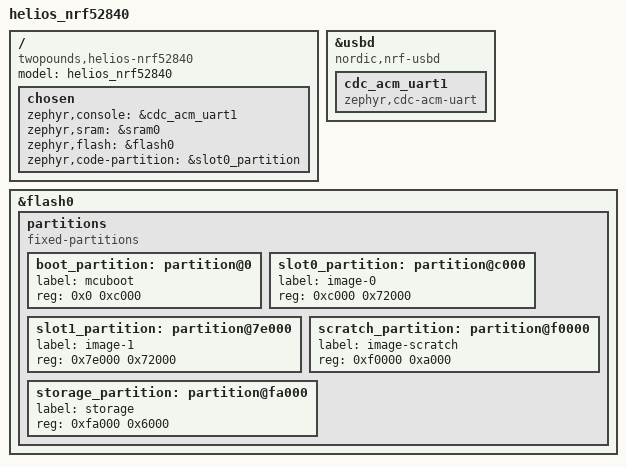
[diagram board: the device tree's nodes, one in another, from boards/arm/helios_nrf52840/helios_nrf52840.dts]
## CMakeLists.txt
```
# SPDX-License-Identifier: Apache-2.0

cmake_minimum_required(VERSION 3.20.0)
# Re-direct the directory where the 'boards' directory is found from
# $ZEPHYR_BASE to this directory.
list(PREPEND BOARD_ROOT ${CMAKE_CURRENT_SOURCE_DIR})

# you can redefine the log levels for the serial modules like this (1=Error,2=Warning,3=Info,4=Debug):
add_compile_definitions(SERIAL_LOG_LEVEL=4 BLE_SERIAL_LOG_LEVEL=3)

find_package(Zephyr REQUIRED HINTS $ENV{ZEPHYR_BASE})
project(Helios)

target_sources(app PRIVATE src/main.c src/serial.c src/serial_internal.c src/uart_serial.c src/ble_serial.c src/cmd_parser.c)
```

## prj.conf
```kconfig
#logging
CONFIG_LOG=y
CONFIG_LOG_DEFAULT_LEVEL=3
CONFIG_LOG_BACKEND_RTT=y
CONFIG_LOG_BACKEND_UART=n

#bluetooth
CONFIG_BT=y
CONFIG_BT_PERIPHERAL=y
CONFIG_BT_NUS=y
CONFIG_BT_DEVICE_NAME="Helios"
CONFIG_BT_MAX_CONN=1
CONFIG_BT_LL_SOFTDEVICE=y

#adc
CONFIG_ADC=y

#increase bt throughput
#CONFIG_BT_GATT_CLIENT=y
#CONFIG_BT_BUF_ACL_RX_SIZE=251
#CONFIG_BT_BUF_ACL_TX_SIZE=251
#CONFIG_BT_L2CAP_TX_MTU=257
#CONFIG_BT_CTLR_DATA_LENGTH_MAX=251
#CONFIG_BT_CTLR_ADV_DATA_LEN_MAX=256
```

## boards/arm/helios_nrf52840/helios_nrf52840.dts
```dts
// Copyright (c) 2023 Nordic Semiconductor ASA
// SPDX-License-Identifier: Apache-2.0

/dts-v1/;
#include <nordic/nrf52840_qiaa.dtsi>

/ {
	model = "helios_nrf52840";
	compatible = "twopounds,helios-nrf52840";

	chosen {
		zephyr,console = &cdc_acm_uart1; // original from manuel
		zephyr,sram = &sram0;
		zephyr,flash = &flash0;
		zephyr,code-partition = &slot0_partition;
	};
};

zephyr_udc0: &usbd {
	compatible = "nordic,nrf-usbd";
	status = "okay";
	cdc_acm_uart1: cdc_acm_uart1 {
		compatible = "zephyr,cdc-acm-uart";
	};
};


&flash0 {
	partitions {
		compatible = "fixed-partitions";
		#address-cells = <1>;
		#size-cells = <1>;

		boot_partition: partition@0 {
			label = "mcuboot";
			reg = <0x0 0xc000>;
		};
		slot0_partition: partition@c000 {
			label = "image-0";
			reg = <0xc000 0x72000>;
		};
		slot1_partition: partition@7e000 {
			label = "image-1";
			reg = <0x7e000 0x72000>;
		};
		scratch_partition: partition@f0000 {
			label = "image-scratch";
			reg = <0xf0000 0xa000>;
		};
		storage_partition: partition@fa000 {
			label = "storage";
			reg = <0xfa000 0x6000>;
		};
	};
};
```

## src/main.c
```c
/*
 * Copyright (c) 2012-2014 Wind River Systems, Inc.
 *
 * SPDX-License-Identifier: Apache-2.0
 */

#include <zephyr/kernel.h>
#include <zephyr/bluetooth/bluetooth.h>
#include "serial.h"

void main(void)
{
	serial_enable(SERIAL_TYPE_UART|SERIAL_TYPE_BLE);
	serial_set_end_character_list("\n", 1);
	serial_sendf(K_FOREVER, "Hello World!\n");
	
	while (true)
	{
		serial_line_t const * p_line = serial_get_line(K_FOREVER);
		serial_send(K_FOREVER, p_line->p_data, p_line->len);
	   	serial_sendf(K_FOREVER, "Hello World\n");
	}
}
```

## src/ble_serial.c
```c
#include "ble_serial.h"

#include <stdio.h>

#include <zephyr/logging/log.h>
#include <zephyr/bluetooth/bluetooth.h>
#include <zephyr/bluetooth/gatt.h>
#include <bluetooth/services/nus.h>

#include "serial_internal.h"


#ifdef CONFIG_BT
#ifdef CONFIG_BT_PERIPHERAL
#ifdef CONFIG_BT_NUS
#ifdef CONFIG_BT_DEVICE_NAME
#if CONFIG_BT==1
#if CONFIG_BT_PERIPHERAL==1
#if CONFIG_BT_NUS==1
#define BLE_SERIAL_REQUIREMENTS_FULLFILLED 1
#endif
#endif
#endif
#endif
#endif
#endif
#endif

#ifdef BLE_SERIAL_REQUIREMENTS_FULLFILLED
//////////////////////////////////////////////////////////////////////////////////////////////////////////////////////////
// DEFINITIONS AND STATIC VARIABLES
#ifndef BLE_SERIAL_LOG_LEVEL
#ifdef SERIAL_LOG_LEVEL
#define BLE_SERIAL_LOG_LEVEL SERIAL_LOG_LEVEL
#else
#define BLE_SERIAL_LOG_LEVEL LOG_LEVEL_WRN
#endif // SERIAL_LOG_LEVEL
#endif // !BLE_SERIAL_LOG_LEVEL

#define LOG_MODULE_NAME ble_serial
LOG_MODULE_REGISTER(LOG_MODULE_NAME, BLE_SERIAL_LOG_LEVEL);

#ifndef BLE_SERIAL_INPUT_BUFFER_SIZE
#ifdef SERIAL_INPUT_BUFFER_SIZE
#define BLE_SERIAL_INPUT_BUFFER_SIZE SERIAL_INPUT_BUFFER_SIZE
#else
#define BLE_SERIAL_INPUT_BUFFER_SIZE 256
#endif // SERIAL_INPUT_BUFFER_SIZE
#endif // !BLE_SERIAL_BUFFER_SIZE

#ifndef BLE_SERIAL_OUTPUT_BUFFER_SIZE
#ifdef SERIAL_OUTPUT_BUFFER_SIZE
#define BLE_SERIAL_OUTPUT_BUFFER_SIZE SERIAL_OUTPUT_BUFFER_SIZE
#else
#define BLE_SERIAL_OUTPUT_BUFFER_SIZE 256
#endif // SERIAL_OUTPUT_BUFFER_SIZE
#endif // !BLE_SERIAL_BUFFER_SIZE

#ifndef BLE_SERIAL_CALLBACK_LIMIT
#define BLE_SERIAL_CALLBACK_LIMIT 1
#endif // !BLE_SERIAL_CALLBACK_LIMIT

#define DEVICE_NAME CONFIG_BT_DEVICE_NAME
#define DEVICE_NAME_LEN (sizeof(CONFIG_BT_DEVICE_NAME) - 1)

static const struct bt_data advertising_data[] = {
	BT_DATA_BYTES(BT_DATA_FLAGS, (BT_LE_AD_GENERAL | BT_LE_AD_NO_BREDR)),
	BT_DATA(BT_DATA_NAME_COMPLETE, DEVICE_NAME, DEVICE_NAME_LEN),
};

static K_SEM_DEFINE(sem_wait_init, 0, 1);
static K_SEM_DEFINE(sem_data_ready, 0, 1);
static K_SEM_DEFINE(sem_wait_for_tx, 1, 1);

static bool enabled = false;
static char input_buffer[BLE_SERIAL_INPUT_BUFFER_SIZE + 1];
static char output_buffer[BLE_SERIAL_OUTPUT_BUFFER_SIZE + 1];
static char line_buffer[BLE_SERIAL_INPUT_BUFFER_SIZE + 1];

static serial_internal_line_t line = { 
	.mutable = { 
	.len = 0,
	.p_buffer = line_buffer,
	},
};

static int start_index = 0;
static int bytes_in_buffer = 0;
static int bt_data_len = 20;

static char const * end_character_list = NULL;
static int end_character_count = 0;

static serial_event_callback_t callback_list[BLE_SERIAL_CALLBACK_LIMIT] = { NULL };
static serial_event_t event;

//////////////////////////////////////////////////////////////////////////////////////////////////////////////////////////


//////////////////////////////////////////////////////////////////////////////////////////////////////////////////////////
// STATIC FUNCTION DECLARATIONS
static void fire_callbacks(serial_event_t const * p_evt);
//////////////////////////////////////////////////////////////////////////////////////////////////////////////////////////


//////////////////////////////////////////////////////////////////////////////////////////////////////////////////////////
// EVENT HANDLERS
static void bt_ready(int err)
{
	if (err)
	{
		LOG_ERR("bt_enable returned %d", err);
	}
	else
	{
		k_sem_give(&sem_wait_init);
	}
}

static void connected(struct bt_conn *conn, uint8_t err)
{
	if (err)
	{
		LOG_ERR("Connect failed (err: %d)", err);
	}
	else
	{
		LOG_INF("Connected");
	}
	LOG_DBG("MTU size is: %d", bt_gatt_get_mtu(conn));
}

static void disconnected(struct bt_conn *conn, uint8_t reason)
{
	LOG_INF("Disconnected (Reason: %d)", reason);
}

static bool le_param_req(struct bt_conn *conn, struct bt_le_conn_param *param)
{
	LOG_DBG("Connection parameters requested: \
	            \n\tInterval-Min: %d \
	            \n\tInterval-Max: %d \
	            \n\tLatency: %d \
	            \n\tTimeout: %d",
		param->interval_min,
		param->interval_max,
		param->latency,
		param->timeout);
    
	LOG_DBG("MTU size is: %d", bt_gatt_get_mtu(conn));

	return true;
}

static void gatt_exchange_cb(struct bt_conn *conn, uint8_t err, struct bt_gatt_exchange_params *params)
{
	LOG_DBG("MTU size after exchange is: %d", bt_gatt_get_mtu(conn));
	bt_data_len = bt_gatt_get_mtu(conn) - 3;
}

static void le_param_updated(struct bt_conn *conn, uint16_t interval, uint16_t latency, uint16_t timeout)
{
	LOG_DBG("Connection parameters updated: \
	        \n\tInterval: %d \
	        \n\tLatency: %d \
	        \n\tTimeout: %d",
		interval,
		latency,
		timeout);
	
#ifdef CONFIG_BT_GATT_CLIENT
#if CONFIG_BT_GATT_CLIENT==1
	LOG_DBG("MTU size is: %d", bt_gatt_get_mtu(conn));
	static struct bt_gatt_exchange_params params = {
		.func = gatt_exchange_cb,
	};

	bt_gatt_exchange_mtu(conn, &params);
#endif
#endif
}

static void nus_received(struct bt_conn *conn, const uint8_t *const data, uint16_t len)
{
	int bytes_to_copy = len;
	while (bytes_to_copy > 0)
	{
		int buffer_index = (start_index + bytes_in_buffer) % BLE_SERIAL_INPUT_BUFFER_SIZE;
		int free_space = (BLE_SERIAL_INPUT_BUFFER_SIZE - buffer_index);
		int part_to_copy = (len < free_space) ? len : free_space;
		memcpy(input_buffer + buffer_index, data, part_to_copy);
		bytes_to_copy -= part_to_copy;
		bytes_in_buffer += part_to_copy;
	}
	k_sem_give(&sem_data_ready);
	LOG_DBG("Received %d bytes, %d bytes in buffer", len, bytes_in_buffer);
	event.type = SERIAL_EVENT_TYPE_NEW_DATA_RECEIVED;
	event.data.new_data.count = len;
	event.data.new_data.p_buf = data;
	fire_callbacks(&event);
}

static void nus_sent(struct bt_conn *conn)
{
	k_sem_give(&sem_wait_for_tx);
}

static void nus_send_enabled(enum bt_nus_send_status status)
{
	
}
//////////////////////////////////////////////////////////////////////////////////////////////////////////////////////////


//////////////////////////////////////////////////////////////////////////////////////////////////////////////////////////
// STATIC FUNCTIONS
static void fire_callbacks(serial_event_t const * p_evt)
{
	for (int i = 0; i < BLE_SERIAL_CALLBACK_LIMIT; i++)
	{
		if (callback_list[i] != NULL)
		{
			callback_list[i](p_evt);
		}
	}
}
//////////////////////////////////////////////////////////////////////////////////////////////////////////////////////////

serial_ret_code_t ble_serial_add_callback(serial_event_callback_t callback)
{
	for (int i = 0; i < BLE_SERIAL_CALLBACK_LIMIT; i++)
	{
		if (callback_list[i] == NULL)
		{
			callback_list[i] = callback;
			return SERIAL_RET_CODE_SUCCESS;
		}
	}
	return SERIAL_RET_CODE_ERROR_NO_MEMORY;
}

serial_ret_code_t ble_serial_remove_callback(serial_event_callback_t callback)
{
	for (int i = 0; i < BLE_SERIAL_CALLBACK_LIMIT; i++)
	{
		if (callback_list[i] == callback)
		{
			callback_list[i] = NULL;
			return SERIAL_RET_CODE_SUCCESS;
		}
	}
	return SERIAL_RET_CODE_ERROR_NO_MEMORY;
}

serial_ret_code_t ble_serial_enable()
{
	k_sem_reset(&sem_wait_init);
	
	static struct bt_conn_cb connection_callbacks = {
		.connected = connected,
		.disconnected = disconnected,
		.le_param_req = le_param_req,
		.le_param_updated = le_param_updated,
	};
	bt_conn_cb_register(&connection_callbacks);
	
	int err;
	err = bt_enable(bt_ready);
	if (err == -EALREADY)
	{
		LOG_INF("bt already enabled, will instead attach nus service to existing ble interface");
		return ble_serial_attach();
	}
	else if (err)
	{
		LOG_ERR("bt_enable returned %d", err);
		return SERIAL_RET_CODE_ERROR_DEVICE_NOT_READY;
	}
	err = k_sem_take(&sem_wait_init, K_MSEC(10));
	if (err)
	{
		LOG_ERR("bt_enable timed out %d", err);
		return SERIAL_RET_CODE_ERROR_DEVICE_NOT_READY;
	}
	
	static struct bt_nus_cb nus_callbacks = {
		.received = nus_received,
		.sent = nus_sent,
		.send_enabled = nus_send_enabled,
	};
	err = bt_nus_init(&nus_callbacks);
	if (err)
	{
		LOG_ERR("could not init nus (err = %d)", err);
		return SERIAL_RET_CODE_ERROR_DEVICE_NOT_READY;
	}
	
	struct bt_le_adv_param * adv_params = BT_LE_ADV_CONN;
	adv_params->interval_min = BT_GAP_ADV_FAST_INT_MIN_1;
	adv_params->interval_max = BT_GAP_ADV_FAST_INT_MAX_1;
	err = bt_le_adv_start(adv_params, advertising_data, ARRAY_SIZE(advertising_data), NULL, 0);
	if (err)
	{
		LOG_ERR("could not start advertising (err = %d)", err);
		return SERIAL_RET_CODE_ERROR_DEVICE_NOT_READY;
	}
	
	k_sem_give(&sem_wait_for_tx);
	enabled = true;
	
	return SERIAL_RET_CODE_SUCCESS;
}

serial_ret_code_t ble_serial_attach()
{
	static struct bt_conn_cb connection_callbacks = {
		.connected = connected,
		.disconnected = disconnected,
		.le_param_req = le_param_req,
		.le_param_updated = le_param_updated,
	};
	bt_conn_cb_register(&connection_callbacks);
	
	int err;
	static struct bt_nus_cb nus_callbacks = {
		.received = nus_received,
		.sent = nus_sent,
		.send_enabled = nus_send_enabled,
	};
	err = bt_nus_init(&nus_callbacks);
	if (err)
	{
		LOG_ERR("could not init nus (err = %d)", err);
		return SERIAL_RET_CODE_ERROR_DEVICE_NOT_READY;
	}
	
	k_sem_give(&sem_wait_for_tx);
	enabled = true;
	
	return SERIAL_RET_CODE_SUCCESS;
}

serial_ret_code_t ble_serial_disable()
{
	
	return SERIAL_RET_CODE_ERROR_UNKNOWN;
}

serial_ret_code_t ble_serial_detach()
{
	
	return SERIAL_RET_CODE_ERROR_UNKNOWN;
}

serial_line_t const * ble_serial_get_line(k_timeout_t timeout)
{
	LOG_DBG("getting next line");
	line.mutable.len = 0;
	if (!enabled)
	{
		LOG_ERR("ble_serial not enabled");
		return &(line.fixed);
	}
	
	return serial_internal_get_line(&sem_data_ready, timeout, &line, input_buffer, BLE_SERIAL_INPUT_BUFFER_SIZE, &start_index, &bytes_in_buffer, end_character_list, end_character_count, fire_callbacks);
}

serial_ret_code_t ble_serial_send(k_timeout_t timeout, char const * p_data, int len)
{
	if (len == 0) return SERIAL_RET_CODE_SUCCESS;
	
	if (k_sem_take(&sem_wait_for_tx, timeout) != 0)
	{
		LOG_WRN("uart tx busy");
		return SERIAL_RET_CODE_ERROR_BUSY;
	}
	
	serial_ret_code_t ret_code = SERIAL_RET_CODE_SUCCESS;
	int bytes_sent = 0;
	while (bytes_sent < len)
	{
		int bytes_to_send = ((len - bytes_sent) < bt_data_len) ? (len - bytes_sent) : bt_data_len;
		int err = bt_nus_send(NULL, p_data + bytes_sent, bytes_to_send);
		if (err != 0)
		{
			k_sem_give(&sem_wait_for_tx);
			if (err != -ENOTCONN)
			{
				LOG_ERR("bt_nus_send returned error: %d", err);
				ret_code = SERIAL_RET_CODE_ERROR_DEVICE_NOT_READY;
			}
			break;
		}
		bytes_sent += bytes_to_send;
		LOG_INF("%d bytes sent (of %d)", bytes_sent, len);
	}
	
	return ret_code;
}

serial_ret_code_t ble_serial_vsendf(k_timeout_t timeout, const char * format, va_list args)
{
	if (k_sem_take(&sem_wait_for_tx, timeout) != 0)
	{
		LOG_WRN("uart tx busy");
		return SERIAL_RET_CODE_ERROR_BUSY;
	}
	k_sem_give(&sem_wait_for_tx);
	
	int len = vsnprintf(output_buffer, BLE_SERIAL_OUTPUT_BUFFER_SIZE, format, args);
	if ((len < 0) || (len > BLE_SERIAL_OUTPUT_BUFFER_SIZE)) return SERIAL_RET_CODE_ERROR_BUFFER_FULL;
	return ble_serial_send(timeout, output_buffer, len);
}

serial_ret_code_t ble_serial_sendf(k_timeout_t timeout, char const * format, ...)
{
	va_list args;
	va_start(args, format);
	serial_ret_code_t result = ble_serial_vsendf(timeout, format, args);
	va_end(args);
	return result;
}

serial_ret_code_t ble_serial_set_end_character_list(char const * p_list, int len)
{
	end_character_count = len;
	end_character_list = p_list;
	LOG_INF("end character list updated");
	return SERIAL_RET_CODE_SUCCESS;
}


#else
#ifndef BLE_SERIAL_LOG_LEVEL
#ifdef SERIAL_LOG_LEVEL
#define BLE_SERIAL_LOG_LEVEL SERIAL_LOG_LEVEL
#else
#define BLE_SERIAL_LOG_LEVEL LOG_LEVEL_WRN
#endif // SERIAL_LOG_LEVEL
#endif // !BLE_SERIAL_LOG_LEVEL

#define LOG_MODULE_NAME ble_serial
LOG_MODULE_REGISTER(LOG_MODULE_NAME, BLE_SERIAL_LOG_LEVEL);
serial_ret_code_t ble_serial_add_callback(serial_event_callback_t callback)
{
	LOG_ERR("this module uses nordic uart service (CONFIG_BT=y,CONFIG_BT_PERIPHERAL=y,CONFIG_BT_NUS=y,CONFIG_BT_DEVICE_NAME=\"[name]\")");
	return SERIAL_RET_CODE_ERROR_DEVICE_NOT_READY;
}

serial_ret_code_t ble_serial_remove_callback(serial_event_callback_t callback)
{
	LOG_ERR("this module uses nordic uart service (CONFIG_BT=y,CONFIG_BT_PERIPHERAL=y,CONFIG_BT_NUS=y,CONFIG_BT_DEVICE_NAME=\"[name]\")");
	return SERIAL_RET_CODE_ERROR_DEVICE_NOT_READY;
}

serial_ret_code_t ble_serial_enable()
{
	LOG_ERR("this module uses nordic uart service (CONFIG_BT=y,CONFIG_BT_PERIPHERAL=y,CONFIG_BT_NUS=y,CONFIG_BT_DEVICE_NAME=\"[name]\")");
	return SERIAL_RET_CODE_ERROR_DEVICE_NOT_READY;
}

serial_ret_code_t ble_serial_attach()
{
	LOG_ERR("this module uses nordic uart service (CONFIG_BT=y,CONFIG_BT_PERIPHERAL=y,CONFIG_BT_NUS=y,CONFIG_BT_DEVICE_NAME=\"[name]\")");
	return SERIAL_RET_CODE_ERROR_DEVICE_NOT_READY;
}

serial_ret_code_t ble_serial_disable()
{
	LOG_ERR("this module uses nordic uart service (CONFIG_BT=y,CONFIG_BT_PERIPHERAL=y,CONFIG_BT_NUS=y,CONFIG_BT_DEVICE_NAME=\"[name]\")");
	return SERIAL_RET_CODE_ERROR_DEVICE_NOT_READY;
}

serial_ret_code_t ble_serial_detach()
{
	LOG_ERR("this module uses nordic uart service (CONFIG_BT=y,CONFIG_BT_PERIPHERAL=y,CONFIG_BT_NUS=y,CONFIG_BT_DEVICE_NAME=\"[name]\")");
	return SERIAL_RET_CODE_ERROR_DEVICE_NOT_READY;
}

serial_line_t const * ble_serial_get_line(k_timeout_t timeout)
{
	static serial_line_t const line = { 0 };
	LOG_ERR("this module uses nordic uart service (CONFIG_BT=y,CONFIG_BT_PERIPHERAL=y,CONFIG_BT_NUS=y,CONFIG_BT_DEVICE_NAME=\"[name]\")");
	return &line;
}

serial_ret_code_t ble_serial_send(k_timeout_t timeout, char const * p_data, int len)
{
	LOG_ERR("this module uses nordic uart service (CONFIG_BT=y,CONFIG_BT_PERIPHERAL=y,CONFIG_BT_NUS=y,CONFIG_BT_DEVICE_NAME=\"[name]\")");
	return SERIAL_RET_CODE_ERROR_DEVICE_NOT_READY;
}

serial_ret_code_t ble_serial_vsendf(k_timeout_t timeout, const char * format, va_list args)
{
	LOG_ERR("this module uses nordic uart service (CONFIG_BT=y,CONFIG_BT_PERIPHERAL=y,CONFIG_BT_NUS=y,CONFIG_BT_DEVICE_NAME=\"[name]\")");
	return SERIAL_RET_CODE_ERROR_DEVICE_NOT_READY;
}

serial_ret_code_t ble_serial_sendf(k_timeout_t timeout, char const * format, ...)
{
	LOG_ERR("this module uses nordic uart service (CONFIG_BT=y,CONFIG_BT_PERIPHERAL=y,CONFIG_BT_NUS=y,CONFIG_BT_DEVICE_NAME=\"[name]\")");
	return SERIAL_RET_CODE_ERROR_DEVICE_NOT_READY;
}

serial_ret_code_t ble_serial_set_end_character_list(char const * p_list, int len)
{
	LOG_ERR("this module uses nordic uart service (CONFIG_BT=y,CONFIG_BT_PERIPHERAL=y,CONFIG_BT_NUS=y,CONFIG_BT_DEVICE_NAME=\"[name]\")");
	return SERIAL_RET_CODE_ERROR_DEVICE_NOT_READY;
}
#endif
```

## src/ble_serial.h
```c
#ifndef BLE_SERIAL_H_
#define BLE_SERIAL_H_

#include <stddef.h>

#include <zephyr/kernel.h>

#include "serial.h"

serial_ret_code_t ble_serial_add_callback(serial_event_callback_t callback);
serial_ret_code_t ble_serial_remove_callback(serial_event_callback_t callback);
serial_ret_code_t ble_serial_enable();
serial_ret_code_t ble_serial_attach();
serial_ret_code_t ble_serial_disable();
serial_ret_code_t ble_serial_detach();
serial_line_t const * ble_serial_get_line(k_timeout_t timeout);
serial_ret_code_t ble_serial_send(k_timeout_t timeout, char const * p_data, int len);
serial_ret_code_t ble_serial_vsendf(k_timeout_t timeout, const char * format, va_list args);
serial_ret_code_t ble_serial_sendf(k_timeout_t timeout, char const * format, ...);
serial_ret_code_t ble_serial_set_end_character_list(char const * p_list, int len);

#endif  /* _ BLE_SERIAL_H_ */
```

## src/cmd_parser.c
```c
/*
 * command_parser.c
 *
 * Created: 21.01.2020 08:49:50
 *  Author: manuel.martin
 */ 

#include "cmd_parser.h"

#include <stddef.h>
#include <string.h>
#include <stdio.h>

///////////////////////////////////////////////////////////////////////////////////////////////////////////////////////////
/// type definitions
///////////////////////////////////////////////////////////////////////////////////////////////////////////////////////////
typedef struct print_line_values_s
{
	int command_len;
	int description_len;
	int complete_len;
} print_line_values_t;
///////////////////////////////////////////////////////////////////////////////////////////////////////////////////////////

///////////////////////////////////////////////////////////////////////////////////////////////////////////////////////////
/// static function declarations
///////////////////////////////////////////////////////////////////////////////////////////////////////////////////////////
static int count_whitespaces(char const * arg, int len);
static bool is_whitespace(char c);
static bool has_suffix(char const * arg, int len, char const * suffix, int suffix_len);
static bool hex_arg_to_int(char const * arg, int len, int * result);
static bool binary_arg_to_int(char const * arg, int len, int * result);
static bool decimal_arg_to_int(char const * arg, int len, int * result);
///////////////////////////////////////////////////////////////////////////////////////////////////////////////////////////

///////////////////////////////////////////////////////////////////////////////////////////////////////////////////////////
/// static function definitions
///////////////////////////////////////////////////////////////////////////////////////////////////////////////////////////
static int count_whitespaces(char const * arg, int len)
{
	for(int i = 0; i < len; i++)
	{
		if (!is_whitespace(arg[i])) return i;
	}
	return len;
}

static bool is_whitespace(char c)
{
	char const whitespaces[] = { '\n', '\t', ' ' };
	for (int i = 0; i < sizeof(whitespaces); i++)
	{
		if (c == whitespaces[i]) return true;
	}
	return false;
}

static bool has_suffix(char const * arg, int len, char const * suffix, int suffix_len)
{
	if (len < suffix_len) return false;
	if (memcmp(arg, suffix, suffix_len) == 0) return true;
	return false;
}

static bool hex_arg_to_int(char const * arg, int len, int * result)
{
	*result = 0;
	bool result_generated = false;
	for (int i = 0; i < len + 1; i += 2)
	{
		char const * pos = arg + i;
		int hex_val = 0;
		if (pos[0] >= '0' && pos[0] <= '9') hex_val = (pos[0] - '0') << 4;
		else if (pos[0] >= 'a' && pos[0] <= 'f') hex_val = (pos[0] - 'a' + 10) << 4;
		else if (pos[0] >= 'A' && pos[0] <= 'F') hex_val = (pos[0] - 'A' + 10) << 4;
		else if (is_whitespace(pos[0])) return true;
		if (pos[1] >= '0' && pos[1] <= '9') hex_val += (pos[1] - '0');
		else if (pos[1] >= 'a' && pos[1] <= 'f') hex_val += (pos[1] - 'a' + 10);
		else if (pos[1] >= 'A' && pos[1] <= 'F') hex_val += (pos[1] - 'A' + 10);
		else return false;
		*result = (*result << 8) + hex_val;
		result_generated = true;
	}
	return result_generated;
}

static bool binary_arg_to_int(char const * arg, int len, int * result)
{
	*result = 0;
	for (int i = 0; i < len; i++)
	{
		if (arg[i] == '1') *result = (*result << 1) + 1;
		else if (arg[i] == '0') *result = (*result << 1);
		else if (is_whitespace(arg[i])) return true;
		else return false;
	}
	return len > 0;
}

static bool decimal_arg_to_int(char const * arg, int len, int * result)
{
	*result = 0;
	int sign = 1;
	if (arg[0] == '-')
	{
		sign = -1;
		arg++;
	}
	for (int i = 0; i < len; i++)
	{
		if (arg[i] >= '0' && arg[i] <= '9') *result = (*result * 10) + arg[i] - '0';
		else if (is_whitespace(arg[i]))
		{
			*result *= sign;
			return true;
		}
		else return false;
	}
	*result *= sign;
	return len > 0;
}
///////////////////////////////////////////////////////////////////////////////////////////////////////////////////////////

static int get_index(char const * input, int input_len, cmd_parser_command_t const * command_list, int command_count)
{
	for (int i = 0; i < command_count; i++)
	{
		int command_len = strlen(command_list[i].name);
		if (input_len < command_len) continue;
		if (memcmp(input, command_list[i].name, command_len) != 0) continue;
		if (input_len > (command_len + 1) && input[command_len + 1] > ' ')
		{
			if (input[command_len] != ' ') continue;
		}
		return i;
	}
	return CMD_PARSER_COMMAND_INVALID;
}

static print_line_values_t calculate_print_line_values(cmd_parser_command_t const * command_list, int command_count)
{
	print_line_values_t values = {0};
	for (int i = 0; i < command_count; i++)
	{
		int len = strlen(command_list[i].name);
		if (len > values.command_len) values.command_len = len;
		len = strlen(command_list[i].description);
		if (len > values.description_len) values.description_len = len;
	}
	values.complete_len = values.command_len + values.description_len + 4;
	return values;
}

int cmd_parser_parse(char const * input, int input_len, cmd_parser_command_t const * command_list, int command_count)
{
	int i = get_index(input, input_len, command_list, command_count);
	if (i == CMD_PARSER_COMMAND_INVALID) return CMD_PARSER_COMMAND_INVALID;
	char const * arg = NULL;
	int arg_len = 0;
	int command_len = strlen(command_list[i].name);
	if(input_len > (command_len + 1) && input[command_len] == ' ')
	{
		arg = input + command_len + 1;
		arg_len = input_len - command_len - 1;
	}
	command_list[i].command_fpt(&(command_list[i]), arg, arg_len);
	return i;
}

int cmd_parser_parse_and_set_context(char const * input, int input_len, cmd_parser_command_t * command_list, int command_count, void * p_context)
{
	int i = get_index(input, input_len, command_list, command_count);
	if (i == CMD_PARSER_COMMAND_INVALID) return CMD_PARSER_COMMAND_INVALID;
	char const * arg = NULL;
	int arg_len = 0;
	int command_len = strlen(command_list[i].name);
	if (input_len > (command_len + 1) && input[command_len] == ' ')
	{
		arg = input + command_len + 1;
		arg_len = input_len - command_len - 1;
	}
	command_list[i].p_context = p_context;
	command_list[i].command_fpt(&(command_list[i]), arg, arg_len);
	return i;
}

int cmd_parser_print_command(char * buffer, int buffer_size, cmd_parser_command_t const * command_list, int command_count, int index)
{
	if(index < 0) return 0;
	if(index >= command_count) return 0;
	print_line_values_t line_values = calculate_print_line_values(command_list, command_count);
	if(buffer_size <= line_values.complete_len) return buffer_size - line_values.complete_len - 1;
	int printed = snprintf(buffer, buffer_size, "%s", command_list[index].name);
	for(int i = printed; i < line_values.command_len; i++)
	{
		buffer[i] = ' ';
	}
	printed = line_values.command_len + snprintf(buffer + line_values.command_len, buffer_size - line_values.command_len, " - %s", command_list[index].description);
	return printed;
}

int cmd_parser_print_title(char * buffer, int buffer_size, cmd_parser_command_t const * command_list, int command_count, char const * title)
{
	print_line_values_t line_values = calculate_print_line_values(command_list, command_count);
	if(buffer_size <= line_values.complete_len) return buffer_size - line_values.complete_len - 1;
	int title_len = strlen(title);
	int dashes_count = (line_values.complete_len - title_len) / 2;
	if(dashes_count < 0) return -1;
	memset(buffer, '-', dashes_count);
	snprintf(buffer + dashes_count, buffer_size - dashes_count, title);
	memset(buffer + dashes_count + title_len, '-', line_values.complete_len - dashes_count - title_len);
	buffer[line_values.complete_len] = '\0';
	return line_values.complete_len;
}

bool cmd_parser_arg_to_int(char const * arg, int len, int * result)
{
	int whitespaces = count_whitespaces(arg, len);
	arg += whitespaces;
	len -= whitespaces;
	
	if (has_suffix(arg, len, "0x", 2)) return hex_arg_to_int(arg + 2, len, result);
	if (has_suffix(arg, len, "0b", 2)) return binary_arg_to_int(arg + 2, len, result);
	return decimal_arg_to_int(arg, len, result);
}
```

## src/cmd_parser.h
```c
/*
 * cmd_parser.h
 *
 *	Module to parse custom commands. The commands need to be provided as a pointer to null terminated char arrays:
 *
 * Created: 21.01.2020 08:50:12
 *  Author: manuel.martin
 */ 


#ifndef CMD_PARSER_H_
#define CMD_PARSER_H_

#include <stdbool.h>

#define CMD_PARSER_COMMAND_INVALID -1
#define CMD_PARSER_COUNT(COMMANDS) (sizeof(COMMANDS) / sizeof(COMMANDS[0]))

typedef struct cmd_parser_command_t
{
	char const * name;
	char const * description;
	void(*command_fpt)(struct cmd_parser_command_t const * self, char const * arg, int len);
	void * p_context;
} cmd_parser_command_t;

int cmd_parser_parse(char const * input, int input_len, cmd_parser_command_t const * command_list, int command_count);
int cmd_parser_parse_and_set_context(char const * input, int input_len, cmd_parser_command_t * command_list, int command_count, void * p_context);
int cmd_parser_print_title(char * buffer, int buffer_size, cmd_parser_command_t const * command_list, int command_count, char const * title);
int cmd_parser_print_command(char * buffer, int buffer_size, cmd_parser_command_t const * command_list, int command_count, int index);
bool cmd_parser_arg_to_int(char const * arg, int len, int * result);

#endif /* CMD_PARSER_H_ */
```

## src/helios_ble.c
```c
#include "helios_ble.h"

#include <zephyr/logging/log.h>
#include <zephyr/bluetooth/bluetooth.h>
#include <zephyr/bluetooth/gatt.h>
#include <bluetooth/scan.h>


#define LOG_MODULE_NAME helios_ble
LOG_MODULE_REGISTER(LOG_MODULE_NAME);

#define BT_LE_OPEN_NETWORK_UUID { 0x2c, 0x4c, 0xc0, 0xf0, 0x37, 0x83, 0x84, 0xec, 0x97, 0xac, 0xfb, 0x32 }

typedef struct service_data_s
{
    uint8_t uuid[12];
    uint32_t network_id;
    helios_ble_data_t helios_data;
} service_data_t;
static service_data_t service_data = {
    .uuid = BT_LE_OPEN_NETWORK_UUID,
    .network_id = 0x12345678,
    .helios_data = { 0 },
};
static service_data_t received_service_data;

#define DEVICE_NAME CONFIG_BT_DEVICE_NAME
#define DEVICE_NAME_LEN (sizeof(CONFIG_BT_DEVICE_NAME) - 1)
static const struct bt_data advertising_data[] = {
	BT_DATA(BT_DATA_SVC_DATA128, &service_data, sizeof(service_data)),
};
static struct bt_le_ext_adv *adv;
K_SEM_DEFINE(sem_data_received, 0, 1);

static bool bt_data_parser(struct bt_data * data, void * user_data)
{
	switch (data->type)
	{
//	case BT_DATA_NAME_COMPLETE:
//		if (data->data_len != DEVICE_NAME_LEN) return false;
//		if (memcmp(data->data, DEVICE_NAME, DEVICE_NAME_LEN) != 0) return false;
//		return true;
	case BT_DATA_SVC_DATA128:
		{
            //if (data->data_len != sizeof(service_data_t)) return false;
			//received data might be unaligned therefore we neeed to copy it in an aligned structure
			
			memcpy(&received_service_data, data->data, sizeof(service_data_t));
			if (memcmp(received_service_data.uuid, service_data.uuid, sizeof(service_data.uuid)) != 0) return false;
            if (received_service_data.network_id != service_data.network_id) return false;

            //LOG_INF("Service data received from %d", received_service_data.helios_data.node_id);
            k_sem_give(&sem_data_received);
		}
		return true;
	default:
		return true;
	}
}

static void scan_cb(const bt_addr_le_t *addr, int8_t rssi, uint8_t adv_type, struct net_buf_simple *buf)
{
	bt_data_parse(buf, bt_data_parser, NULL);
    //LOG_INF("advertising received: %d dB, %d bytes", rssi, buf->len);
}

static void connected_cb(struct bt_le_ext_adv *adv, struct bt_le_ext_adv_connected_info *info)
{
	LOG_INF("Connected");
}

static void scanned_cb(struct bt_le_ext_adv *adv, struct bt_le_ext_adv_scanned_info *info)
{
	LOG_INF("Scanned");
}

static void sent_cb(struct bt_le_ext_adv *adv, struct bt_le_ext_adv_sent_info *info)
{
	LOG_INF("Data sent");
}


helios_ble_return_code_t helios_ble_enable()
{
    int err;

    //BLE einschalten
	err = bt_enable(NULL);
	if (err) {
		LOG_ERR("bluetooth init failed (err %d)", err);
		return HELIOS_BLE_RETURN_CODE_ERROR;
	}
	LOG_INF("bluetooth initialized\n");

    //Scanner einschalten
    const struct bt_le_scan_param ble_scan_params = { 
		.interval = 0x0100,
		.window = 0x0100,
		.timeout = 0,
		.type = BT_LE_SCAN_TYPE_PASSIVE,
		.options = BT_LE_SCAN_OPT_NONE,
	};
	
	err = bt_le_scan_start(&ble_scan_params, scan_cb);
	if (err) {
		LOG_ERR("starting scanning failed (err %d)", err);
		return HELIOS_BLE_RETURN_CODE_ERROR;
	}

    //Advertising vorbereiten
    static struct bt_le_adv_param * adv_params;
	adv_params = BT_LE_EXT_ADV_NCONN_NAME;
	
	static struct bt_le_ext_adv_cb ext_adv_cb = {
		.connected = connected_cb,
		.scanned = scanned_cb,
		.sent = sent_cb,
	};
	
	err = bt_le_ext_adv_create(adv_params, &ext_adv_cb, &adv);
	if (err) {
		LOG_ERR("failed to create bt_le_ext_adv struct (err %d)", err);
		return HELIOS_BLE_RETURN_CODE_ERROR;
	}

    return HELIOS_BLE_RETURN_CODE_SUCCESS;
}


helios_ble_return_code_t helios_ble_send(helios_ble_data_t const * p_data)
{
    memcpy(&(service_data.helios_data), p_data, sizeof(helios_ble_data_t));
    int err = bt_le_ext_adv_set_data(adv, advertising_data, ARRAY_SIZE(advertising_data), NULL, 0);
	if (err) {
		LOG_INF("failed to set adv data (err %d)", err);
		return HELIOS_BLE_RETURN_CODE_ERROR;
	}
	struct bt_le_ext_adv_start_param ext_start_param = {
		.num_events = 1,
		.timeout = 10,
	};
	err = bt_le_ext_adv_start(adv, &ext_start_param);
	if (err) {
		LOG_INF("failed to start advertising (err %d)", err);
		return HELIOS_BLE_RETURN_CODE_ERROR;
	}

    return HELIOS_BLE_RETURN_CODE_SUCCESS;
}


helios_ble_data_t const * helios_ble_receive(k_timeout_t timeout)
{
    if(k_sem_take(&sem_data_received, timeout)) return NULL;

    return &received_service_data.helios_data;
}
```

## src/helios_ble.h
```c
#ifndef HELIOS_BLE_H_
#define HELIOS_BLE_H_

#include "stdint.h"
#include <zephyr/kernel.h>

typedef enum helios_ble_return_code_e
{
	HELIOS_BLE_RETURN_CODE_SUCCESS,
    HELIOS_BLE_RETURN_CODE_ERROR,
} helios_ble_return_code_t;

typedef enum helios_ble_pattern_e
{
	PATTERN_TRAIL,
	PATTERN_PRECEDE,
	PATTERN_SYNC,
	PATTERN_ON,
	PATTERN_OFF,
	PATTERN_KNIGHT_RIDER,
} helios_ble_pattern_t;

typedef struct helios_ble_data_s {
    int64_t network_time;
    helios_ble_pattern_t pattern;
    uint8_t node_count;
    uint8_t node_id;
} helios_ble_data_t;

helios_ble_return_code_t helios_ble_enable();
helios_ble_return_code_t helios_ble_send(helios_ble_data_t const * p_data);
helios_ble_data_t const * helios_ble_receive(k_timeout_t timeout);

#endif /* HELIOS_BLE_H_ */
```

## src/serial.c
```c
#include "serial.h"

#include <zephyr/logging/log.h>

#include "uart_serial.h"
#include "ble_serial.h"

//////////////////////////////////////////////////////////////////////////////////////////////////////////////////////////
// DEFINITIONS AND STATIC VARIABLES
#ifndef SERIAL_LOG_LEVEL
#define SERIAL_LOG_LEVEL LOG_LEVEL_WRN
#endif // !SERIAL_LOG_LEVEL

#define LOG_MODULE_NAME serial
LOG_MODULE_REGISTER(LOG_MODULE_NAME, SERIAL_LOG_LEVEL);
//////////////////////////////////////////////////////////////////////////////////////////////////////////////////////////


//////////////////////////////////////////////////////////////////////////////////////////////////////////////////////////
// STATIC FUNCTION DECLARATIONS
static K_SEM_DEFINE(sem_wait_for_data, 0, 1);

static serial_type_t enabled_serial_types = SERIAL_TYPE_NONE;

static char const * end_character_list = NULL;
static int end_character_count = 0;
//////////////////////////////////////////////////////////////////////////////////////////////////////////////////////////


//////////////////////////////////////////////////////////////////////////////////////////////////////////////////////////
// EVENT HANDLERS
void uart_serial_callback(serial_event_t const * p_evt)
{
	switch (p_evt->type)
	{
	case SERIAL_EVENT_TYPE_NEW_DATA_RECEIVED:
		k_sem_give(&sem_wait_for_data);
		LOG_DBG("new data from uart_serial received");
		break;
	default:
		break;
	}
}

void ble_serial_callback(serial_event_t const * p_evt)
{
	switch (p_evt->type)
	{
	case SERIAL_EVENT_TYPE_NEW_DATA_RECEIVED:
		k_sem_give(&sem_wait_for_data);
		LOG_DBG("new data from uart_serial received");
		break;
	default:
		break;
	}
}
//////////////////////////////////////////////////////////////////////////////////////////////////////////////////////////


//////////////////////////////////////////////////////////////////////////////////////////////////////////////////////////
// STATIC FUNCTIONS

//////////////////////////////////////////////////////////////////////////////////////////////////////////////////////////

serial_ret_code_t serial_enable(serial_type_t type)
{
	serial_ret_code_t ret_code = SERIAL_RET_CODE_ERROR_UNKNOWN;
	
	if (type & SERIAL_TYPE_UART)
	{
		ret_code = uart_serial_set_end_character_list(end_character_list, end_character_count);
		if (ret_code != SERIAL_RET_CODE_SUCCESS)
		{
			LOG_ERR("unable to set end-character-list for uart_serial!");
			return ret_code;
		}
		
		ret_code = uart_serial_enable();
		if (ret_code != SERIAL_RET_CODE_SUCCESS)
		{
			LOG_ERR("unable to enable uart_serial!");
			return ret_code;
		}
		ret_code = uart_serial_add_callback(uart_serial_callback);
		if (ret_code != SERIAL_RET_CODE_SUCCESS)
		{
			LOG_ERR("unable to add uart_serial callback!");
			return ret_code;
		}
		enabled_serial_types |= SERIAL_TYPE_UART;
	}
	
	if (type & SERIAL_TYPE_BLE)
	{
		ret_code = ble_serial_set_end_character_list(end_character_list, end_character_count);
		if (ret_code != SERIAL_RET_CODE_SUCCESS)
		{
			LOG_ERR("unable to set end-character-list for ble_serial!");
			return ret_code;
		}
		
		ret_code = ble_serial_enable();
		if (ret_code != SERIAL_RET_CODE_SUCCESS)
		{
			LOG_ERR("unable to enable ble_serial!");
			return ret_code;
		}
		ret_code = ble_serial_add_callback(ble_serial_callback);
		if (ret_code != SERIAL_RET_CODE_SUCCESS)
		{
			LOG_ERR("unable to add ble_serial callback!");
			return ret_code;
		}
		enabled_serial_types |= SERIAL_TYPE_BLE;
	}
	
	return ret_code;
}

serial_ret_code_t serial_disable(serial_type_t type)
{
	serial_ret_code_t ret_code = SERIAL_RET_CODE_SUCCESS;
	
	if (type & enabled_serial_types & SERIAL_TYPE_UART)
	{
		ret_code = uart_serial_disable();
		if (ret_code != SERIAL_RET_CODE_SUCCESS)
		{
			LOG_ERR("unable to disable uart_serial!");
			return ret_code;
		}
		ret_code = uart_serial_remove_callback(uart_serial_callback);
		if (ret_code != SERIAL_RET_CODE_SUCCESS)
		{
			LOG_ERR("unable to remove uart_serial callback!");
			return ret_code;
		}
		enabled_serial_types &= ~SERIAL_TYPE_UART;
	}
	
	if (type & enabled_serial_types & SERIAL_TYPE_BLE)
	{
		ret_code = ble_serial_disable();
		if (ret_code != SERIAL_RET_CODE_SUCCESS)
		{
			LOG_ERR("unable to disable ble_serial!");
			return ret_code;
		}
		ret_code = ble_serial_remove_callback(uart_serial_callback);
		if (ret_code != SERIAL_RET_CODE_SUCCESS)
		{
			LOG_ERR("unable to remove ble_serial callback!");
			return ret_code;
		}
		enabled_serial_types &= ~SERIAL_TYPE_BLE;
	}
	
	return ret_code;
}

serial_line_t const * serial_get_line(k_timeout_t timeout)
{
	static serial_line_t empty_line = { 
		.len = 0,
		.p_data = NULL,
	};
	while (true)
	{
		serial_line_t const * p_line = &empty_line;
		
		if (enabled_serial_types & SERIAL_TYPE_UART)
		{
			p_line = uart_serial_get_line(K_NO_WAIT);
			if (p_line->len > 0) return p_line;
		}
		
		if (enabled_serial_types & SERIAL_TYPE_BLE)
		{
			p_line = ble_serial_get_line(K_NO_WAIT);
			if (p_line->len > 0) return p_line;
		}
		
		if (k_sem_take(&sem_wait_for_data, timeout) != 0)
		{
			LOG_DBG("timeout reached");
			k_sleep(K_MSEC(10));
			return &empty_line;
		}
		
	}
	
}

serial_ret_code_t serial_send(k_timeout_t timeout, char const * p_data, int len)
{
	serial_ret_code_t ret_code = SERIAL_RET_CODE_ERROR_UNKNOWN;
	
	if (enabled_serial_types & SERIAL_TYPE_UART)
	{
		ret_code = uart_serial_send(timeout, p_data, len);
		if (ret_code != SERIAL_RET_CODE_SUCCESS)
		{
			LOG_ERR("unable to send over uart_serial (code: %d)", ret_code);
		}
	}
	
	if (enabled_serial_types & SERIAL_TYPE_BLE)
	{
		ret_code = ble_serial_send(timeout, p_data, len);
		if (ret_code != SERIAL_RET_CODE_SUCCESS)
		{
			LOG_ERR("unable to send over ble_serial (code: %d)", ret_code);
		}
	}
	
	return ret_code;
}

serial_ret_code_t serial_sendf(k_timeout_t timeout, char const * format, ...)
{
	va_list args;
	va_start(args, format);
	serial_ret_code_t ret_code = SERIAL_RET_CODE_ERROR_UNKNOWN;
	
	if (enabled_serial_types & SERIAL_TYPE_UART)
	{
		ret_code = uart_serial_vsendf(timeout, format, args);
		if (ret_code != SERIAL_RET_CODE_SUCCESS)
		{
			LOG_ERR("unable to send over uart_serial (code: %d)", ret_code);
		}
	}
	
	if (enabled_serial_types & SERIAL_TYPE_BLE)
	{
		ret_code = ble_serial_vsendf(timeout, format, args);
		if (ret_code != SERIAL_RET_CODE_SUCCESS)
		{
			LOG_ERR("unable to send over ble_serial (code: %d)", ret_code);
		}
	}
	
	va_end(args);
	return ret_code;
}

serial_ret_code_t serial_set_end_character_list(char const * p_list, int len)
{
	serial_ret_code_t ret_code = SERIAL_RET_CODE_SUCCESS;
	
	end_character_list = p_list;
	end_character_count = len;
	
	if (enabled_serial_types & SERIAL_TYPE_UART)
	{
		ret_code = uart_serial_set_end_character_list(p_list, len);
		if (ret_code != SERIAL_RET_CODE_SUCCESS)
		{
			LOG_ERR("unable to update uart_serial end-character list!");
			return ret_code;
		}
	}
	
	if (enabled_serial_types & SERIAL_TYPE_BLE)
	{
		ret_code = ble_serial_set_end_character_list(p_list, len);
		if (ret_code != SERIAL_RET_CODE_SUCCESS)
		{
			LOG_ERR("unable to update uart_serial end-character list!");
			return ret_code;
		}
	}
	
	return ret_code;
}
```

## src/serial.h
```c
#ifndef SERIAL_H_
#define SERIAL_H_

#include <stddef.h>

#include <zephyr/kernel.h>

typedef enum serial_ret_code_e
{
	SERIAL_RET_CODE_SUCCESS,
	SERIAL_RET_CODE_ERROR_UNKNOWN = -1,
	SERIAL_RET_CODE_ERROR_DEVICE_NOT_READY = -2,
	SERIAL_RET_CODE_ERROR_TIMEOUT = -3,
	SERIAL_RET_CODE_ERROR_BUFFER_FULL = -4,
	SERIAL_RET_CODE_ERROR_BUSY = -5,
	SERIAL_RET_CODE_ERROR_NO_MEMORY = -6,
} serial_ret_code_t;

typedef enum serial_type_e
{
	SERIAL_TYPE_NONE = 0x00,
	SERIAL_TYPE_UART = (1<<0),
	SERIAL_TYPE_BLE = (1<<1),
	SERIAL_TYPE_ALL = 0xFFFFFFFF,
} serial_type_t;

typedef struct serial_event_new_data_s
{
	size_t count;
	char const * p_buf;
} serial_event_new_data_t;

typedef struct serial_event_buff_ovf_s
{
	size_t count;
} serial_event_buff_ovf_t;


typedef struct serial_event_s
{
	enum {
		SERIAL_EVENT_TYPE_NEW_DATA_RECEIVED,
		SERIAL_EVENT_TYPE_BUFFER_OVERFLOW,
	} type;
	union {
		serial_event_new_data_t new_data;
		serial_event_buff_ovf_t buf_ovf;
	} data;
} serial_event_t;

typedef void(*serial_event_callback_t)(serial_event_t const * p_evt);

typedef struct serial_line_s
{
	size_t const len;
	char const * const p_data;
} serial_line_t;

serial_ret_code_t serial_enable(serial_type_t type);
serial_ret_code_t serial_disable(serial_type_t type);
serial_line_t const * serial_get_line(k_timeout_t timeout);
serial_ret_code_t serial_send(k_timeout_t timeout, char const * p_data, int len);
serial_ret_code_t serial_sendf(k_timeout_t timeout, char const * format, ...);
serial_ret_code_t serial_set_end_character_list(char const * p_list, int len);


#endif  /* _ SERIAL_H_ */
```

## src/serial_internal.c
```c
#include "serial_internal.h"

#include <zephyr/logging/log.h>

//////////////////////////////////////////////////////////////////////////////////////////////////////////////////////////
// DEFINITIONS AND STATIC VARIABLES
#ifndef SERIAL_INTERNAL_LOG_LEVEL
#ifdef SERIAL_LOG_LEVEL
#define SERIAL_INTERNAL_LOG_LEVEL SERIAL_LOG_LEVEL
#else
#define SERIAL_INTERNAL_LOG_LEVEL LOG_LEVEL_WRN
#endif // SERIAL_LOG_LEVEL
#endif // !SERIAL_INTERNAL_LOG_LEVEL

#define LOG_MODULE_NAME serial_internal
LOG_MODULE_REGISTER(LOG_MODULE_NAME, SERIAL_INTERNAL_LOG_LEVEL);
//////////////////////////////////////////////////////////////////////////////////////////////////////////////////////////

serial_line_t const * serial_internal_get_line(
	struct k_sem * p_sem_data_ready,
	k_timeout_t timeout,
	serial_internal_line_t * p_line,
	uint8_t const * input_buffer,
	size_t const input_buffer_size,
	int * p_input_buffer_index,
	int volatile * p_bytes_in_buffer,
	char const * end_character_list,
	int const end_character_count, 
	serial_event_callback_t fire_callbacks_function)
{
	static serial_event_t event;
	static serial_line_t const empty_line = { 0 };
	
	LOG_DBG("getting next line");
	p_line->mutable.len = 0;
	
	while (true)
	{
		if ((*p_bytes_in_buffer == p_line->mutable.len) && (k_sem_take(p_sem_data_ready, timeout) != 0))
		{
			LOG_DBG("timeout reached");
			return &empty_line;
		}
		
		bool line_end_found = false;

		int bytes_to_check = *p_bytes_in_buffer;
		if (bytes_to_check > input_buffer_size)
		{
			int lost_bytes = *p_bytes_in_buffer - input_buffer_size; 
			*p_bytes_in_buffer -= lost_bytes;
			bytes_to_check = input_buffer_size;
			*p_input_buffer_index = (*p_input_buffer_index + lost_bytes) % input_buffer_size;
			p_line->mutable.len = 0;
			LOG_WRN("overflow! %d bytes overwritten! (StartIndex: %d, BytesInBuffer: %d)", lost_bytes, *p_input_buffer_index, *p_bytes_in_buffer);
			event.type = SERIAL_EVENT_TYPE_BUFFER_OVERFLOW;
			event.data.buf_ovf.count = lost_bytes;
			fire_callbacks_function(&event);
		}
		
		for (int i = p_line->mutable.len; i < bytes_to_check; i++)
		{
			int buffer_index = (*p_input_buffer_index + i) % input_buffer_size;
			p_line->mutable.p_buffer[i] = input_buffer[buffer_index];
			p_line->mutable.len++;
			for (int j = 0; j < end_character_count; j++)
			{
				if (p_line->mutable.p_buffer[i] == end_character_list[j])
				{
					p_line->mutable.p_buffer[p_line->mutable.len] = '\0';
					line_end_found = true;
					break;
				}
			}
			if (line_end_found)
			{
				break;
			}
		}
		
		if ((end_character_count == 0 && p_line->mutable.len > 0) || line_end_found)
		{
			if (*p_bytes_in_buffer > input_buffer_size)
			{
				line_end_found = false;
				p_line->mutable.len = 0;
				LOG_WRN("overflow while copying data to line structure!");
				break;
			}
			*p_input_buffer_index = (*p_input_buffer_index + p_line->mutable.len) % input_buffer_size;
			*p_bytes_in_buffer -= p_line->mutable.len;
			LOG_INF("line with length %d returned, bytes left in buffer: %d", p_line->mutable.len, *p_bytes_in_buffer);
			return &(p_line->fixed);
		}
		
		LOG_DBG("no line in received data, waiting for new data...");
	}
	
	LOG_ERR("fell through line preparation!");
	return &(p_line->fixed);
}
```

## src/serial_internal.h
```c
#ifndef SERIAL_INTERNAL_H_
#define SERIAL_INTERNAL_H_

#include <zephyr/kernel.h>

#include "serial.h"

typedef union serial_internal_line_u
{
	serial_line_t fixed;
	struct modifiable_line_s
	{
		size_t len;
		char * p_buffer;
	} mutable;
} serial_internal_line_t;

serial_line_t const * serial_internal_get_line(
	struct k_sem * p_sem_data_ready,
	k_timeout_t timeout,
	serial_internal_line_t * p_line,
	uint8_t const * input_buffer,
	size_t const input_buffer_size,
	int * p_input_buffer_index,
	int volatile * p_bytes_in_buffer,
	char const * end_character_list,
	int const end_character_count, 
	serial_event_callback_t fire_callbacks_function);

#endif  /* _ SERIAL_INTERNAL_H_ */
```

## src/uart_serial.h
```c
#ifndef UART_SERIAL_H_
#define UART_SERIAL_H_

#include <stddef.h>

#include <zephyr/kernel.h>

#include "serial.h"

serial_ret_code_t uart_serial_add_callback(serial_event_callback_t callback);
serial_ret_code_t uart_serial_remove_callback(serial_event_callback_t callback);
serial_ret_code_t uart_serial_enable();
serial_ret_code_t uart_serial_disable();
serial_line_t const * uart_serial_get_line(k_timeout_t timeout);
serial_ret_code_t uart_serial_send(k_timeout_t timeout, char const * p_data, int len);
serial_ret_code_t uart_serial_vsendf(k_timeout_t timeout, const char * format, va_list args);
serial_ret_code_t uart_serial_sendf(k_timeout_t timeout, char const * format, ...);
serial_ret_code_t uart_serial_set_end_character_list(char const * p_list, int len);


#endif  /* _ UART_SERIAL_H_ */
```
